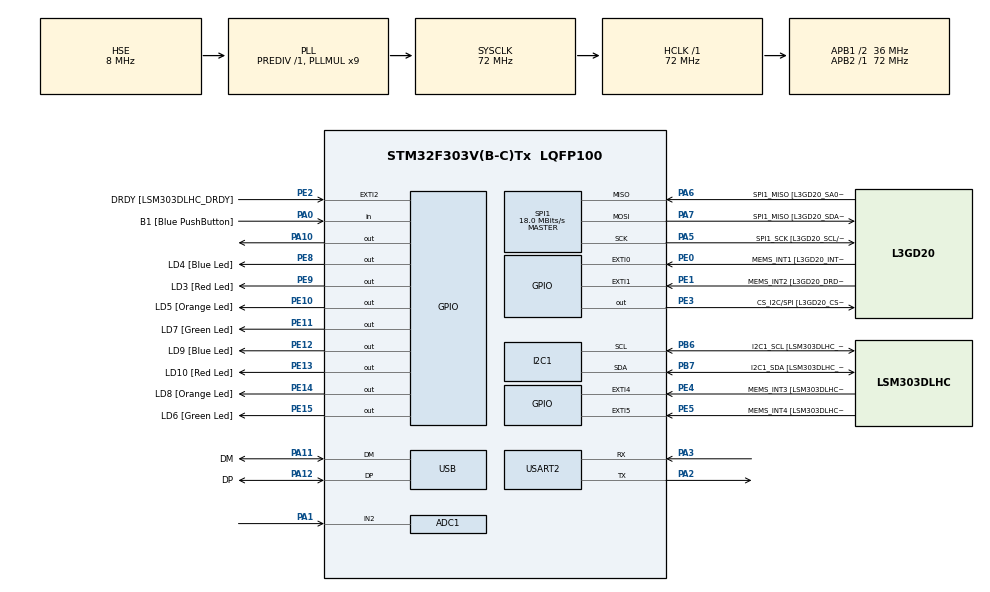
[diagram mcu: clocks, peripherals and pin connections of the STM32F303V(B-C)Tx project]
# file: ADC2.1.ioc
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ADC1.Channel-0\#ChannelRegularConversion=ADC_CHANNEL_2
ADC1.ContinuousConvMode=DISABLE
ADC1.NbrOfConversionFlag=1
ADC1.Offset-0\#ChannelRegularConversion=0
ADC1.OffsetNumber-0\#ChannelRegularConversion=ADC_OFFSET_NONE
ADC1.Rank-0\#ChannelRegularConversion=1
ADC1.SamplingTime-0\#ChannelRegularConversion=ADC_SAMPLETIME_19CYCLES_5
ADC1.SamplingTimeOPAMP-0\#ChannelRegularConversion=ADC_SAMPLETIME_19CYCLES_5
ADC1.master=1
Dma.ADC1.0.Direction=DMA_PERIPH_TO_MEMORY
Dma.ADC1.0.Instance=DMA1_Channel1
Dma.ADC1.0.MemDataAlignment=DMA_MDATAALIGN_WORD
Dma.ADC1.0.MemInc=DMA_MINC_ENABLE
Dma.ADC1.0.Mode=DMA_CIRCULAR
Dma.ADC1.0.PeriphDataAlignment=DMA_PDATAALIGN_WORD
Dma.ADC1.0.PeriphInc=DMA_PINC_DISABLE
Dma.ADC1.0.Priority=DMA_PRIORITY_LOW
Dma.Request0=ADC1
I2C1.Timing-I2C=0x2000090E
Mcu.Family=STM32F3
Mcu.Name=STM32F303V(B-C)Tx
Mcu.Package=LQFP100
NVIC.DMA1_Channel1_IRQn=true\:0\:0\:false\:false\:true\:false\:true\:true
NVIC.PriorityGroup=NVIC_PRIORITYGROUP_0
PA0.GPIO_Label=B1 [Blue PushButton]
PA0.Signal=GPIO_Input
PA1.Mode=IN2-Single-Ended
PA1.Signal=ADC1_IN2
PA10.Signal=GPIO_Output
PA11.GPIO_Label=DM
PA11.Mode=Device
PA11.Signal=USB_DM
PA12.GPIO_Label=DP
PA12.Mode=Device
PA12.Signal=USB_DP
PA13.GPIO_Label=SWDIO
PA13.Mode=Serial_Wire
PA13.Signal=SYS_JTMS-SWDIO
PA14.GPIO_Label=SWCLK
PA14.Mode=Serial_Wire
PA14.Signal=SYS_JTCK-SWCLK
PA2.Mode=Asynchronous
PA2.Signal=USART2_TX
PA3.Mode=Asynchronous
PA3.Signal=USART2_RX
PA5.GPIO_Label=SPI1_SCK [L3GD20_SCL/SPC]
PA5.Mode=Full_Duplex_Master
PA5.Signal=SPI1_SCK
PA6.GPIO_Label=SPI1_MISO [L3GD20_SA0/SDO]
PA6.Mode=Full_Duplex_Master
PA6.Signal=SPI1_MISO
PA7.GPIO_Label=SPI1_MISO [L3GD20_SDA/SDI/SDO]
PA7.Mode=Full_Duplex_Master
PA7.Signal=SPI1_MOSI
PB3.GPIO_Label=SWO
PB3.Signal=SYS_JTDO-TRACESWO
PB6.GPIO_Label=I2C1_SCL [LSM303DLHC_SCL]
PB6.GPIO_Pu=GPIO_PULLUP
PB6.Mode=I2C
PB6.Signal=I2C1_SCL
PB7.GPIO_Label=I2C1_SDA [LSM303DLHC_SDA]
PB7.GPIO_Pu=GPIO_PULLUP
PB7.Mode=I2C
PB7.Signal=I2C1_SDA
PC14-OSC32_IN.GPIO_Label=OSC32_IN
PC14-OSC32_IN.Signal=RCC_OSC32_IN
PC15-OSC32_OUT.GPIO_Label=OSC32_OUT
PC15-OSC32_OUT.Signal=RCC_OSC32_OUT
PE0.GPIO_Label=MEMS_INT1 [L3GD20_INT1]
PE0.GPIO_ModeDefaultEXTI=GPIO_MODE_EVT_RISING
PE0.Signal=GPXTI0
PE1.GPIO_Label=MEMS_INT2 [L3GD20_DRDY/INT2]
PE1.GPIO_ModeDefaultEXTI=GPIO_MODE_EVT_RISING
PE1.Signal=GPXTI1
PE10.GPIO_Label=LD5 [Orange Led]
PE10.Signal=GPIO_Output
PE11.GPIO_Label=LD7 [Green Led]
PE11.Signal=GPIO_Output
PE12.GPIO_Label=LD9 [Blue Led]
PE12.Signal=GPIO_Output
PE13.GPIO_Label=LD10 [Red Led]
PE13.Signal=GPIO_Output
PE14.GPIO_Label=LD8 [Orange Led]
PE14.Signal=GPIO_Output
PE15.GPIO_Label=LD6 [Green Led]
PE15.Signal=GPIO_Output
PE2.GPIO_Label=DRDY [LSM303DLHC_DRDY]
PE2.GPIO_ModeDefaultEXTI=GPIO_MODE_EVT_RISING
PE2.Signal=GPXTI2
PE3.GPIO_Label=CS_I2C/SPI [L3GD20_CS_I2C/SPI]
PE3.Signal=GPIO_Output
PE4.GPIO_Label=MEMS_INT3 [LSM303DLHC_INT1]
PE4.GPIO_ModeDefaultEXTI=GPIO_MODE_EVT_RISING
PE4.Signal=GPXTI4
PE5.GPIO_Label=MEMS_INT4 [LSM303DLHC_INT2]
PE5.GPIO_ModeDefaultEXTI=GPIO_MODE_EVT_RISING
PE5.Signal=GPXTI5
PE8.GPIO_Label=LD4 [Blue Led]
PE8.Signal=GPIO_Output
PE9.GPIO_Label=LD3 [Red Led]
PE9.Signal=GPIO_Output
PF0-OSC_IN.GPIO_Label=OSC_IN
PF0-OSC_IN.Mode=HSE-External-Oscillator
PF0-OSC_IN.Signal=RCC_OSC_IN
PF1-OSC_OUT.GPIO_Label=OSC_OUT
PF1-OSC_OUT.Mode=HSE-External-Oscillator
PF1-OSC_OUT.Signal=RCC_OSC_OUT
ProjectManager.HeapSize=0x200
ProjectManager.StackSize=0x400
ProjectManager.TargetToolchain=MDK-ARM V5.32
RCC.AHBFreq_Value=72000000
RCC.APB1CLKDivider=RCC_HCLK_DIV2
RCC.APB1Freq_Value=36000000
RCC.APB1TimFreq_Value=72000000
RCC.APB2Freq_Value=72000000
RCC.APB2TimFreq_Value=72000000
RCC.CortexFreq_Value=72000000
RCC.HCLKFreq_Value=72000000
RCC.HSE_VALUE=8000000
RCC.HSI_VALUE=8000000
RCC.LSE_VALUE=32768
RCC.PLLMUL=RCC_PLL_MUL9
RCC.PRESCALERUSB=RCC_USBCLKSOURCE_PLL_DIV1_5
RCC.SYSCLKFreq_VALUE=72000000
RCC.SYSCLKSourceVirtual=RCC_SYSCLKSOURCE_PLLCLK
RCC.USBFreq_Value=48000000
SPI1.BaudRatePrescaler=SPI_BAUDRATEPRESCALER_4
SPI1.BaudRatePrescaler-Full_Duplex_Master=SPI_BAUDRATEPRESCALER_2
SPI1.CalculateBaudRate=18.0 MBits/s
SPI1.CalculateBaudRate-Full_Duplex_Master=24.0 MBits/s
SPI1.Direction=SPI_DIRECTION_2LINES
SPI1.Mode=SPI_MODE_MASTER
SPI1.Mode-Full_Duplex_Master=SPI_MODE_MASTER
SPI1.VirtualType=VM_MASTER
USART2.VirtualMode-Asynchronous=VM_ASYNC
board=STM32F3DISCOVERY

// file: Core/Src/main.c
/* USER CODE BEGIN Header */
/**
  ******************************************************************************
  * @file           : main.c
  * @brief          : Main program body
  ******************************************************************************
  * @attention
  *
  * Copyright (c) 2022 STMicroelectronics.
  * All rights reserved.
  *
  * This software is licensed under terms that can be found in the LICENSE file
  * in the root directory of this software component.
  * If no LICENSE file comes with this software, it is provided AS-IS.
  *
  ******************************************************************************
  */
/* USER CODE END Header */
#include "main.h"
#include "adc.h"
#include "dma.h"
#include "i2c.h"
#include "spi.h"
#include "usart.h"
#include "gpio.h"

/* USER CODE BEGIN Includes */
   #include <string.h>
	 #include <stdio.h>
/* USER CODE END Includes */

void SystemClock_Config(void);

int main(void)
{
  /* USER CODE BEGIN 1 */
     uint16_t raw;
	   char msg[10];
  /* USER CODE END 1 */

  /* MCU Configuration--------------------------------------------------------*/

  /* Reset of all peripherals, Initializes the Flash interface and the Systick. */
  HAL_Init();

  /* Configure the system clock */
  SystemClock_Config();

  /* Initialize all configured peripherals */
  MX_GPIO_Init();
  MX_DMA_Init();
  MX_ADC1_Init();
  MX_I2C1_Init();
  MX_SPI1_Init();
  //MX_USB_PCD_Init();
  MX_USART2_UART_Init();
  /* USER CODE BEGIN 2 */
	//GET ADC VALUE
		HAL_ADC_Start(&hadc1);
		HAL_ADC_PollForConversion(&hadc1, HAL_MAX_DELAY);
  /* USER CODE END 2 */

  /* Infinite loop */
  /* USER CODE BEGIN WHILE */
  while (1)
  {
		//test:set gpio pin high
		//HAL_GPIO_WritePin(GPIOA, GPIO_PIN_10, GPIO_PIN_SET);

		raw= HAL_ADC_GetValue(&hadc1);

		//TEST: SET GPIO PIN LOW
		HAL_GPIO_WritePin(GPIOA, GPIO_PIN_10, GPIO_PIN_RESET);

		//Convert to string and print
		sprintf(msg, "%hu\r\n", raw);
		HAL_UART_Transmit(&huart2, (uint8_t*)msg, strlen(msg), HAL_MAX_DELAY);

		HAL_Delay(1);

    /* USER CODE END WHILE */

  }
}

void SystemClock_Config(void)
{
  RCC_OscInitTypeDef RCC_OscInitStruct = {0};
  RCC_ClkInitTypeDef RCC_ClkInitStruct = {0};
  RCC_PeriphCLKInitTypeDef PeriphClkInit = {0};

  /** Initializes the RCC Oscillators according to the specified parameters
  * in the RCC_OscInitTypeDef structure.
  */
  RCC_OscInitStruct.OscillatorType = RCC_OSCILLATORTYPE_HSI|RCC_OSCILLATORTYPE_HSE;
  RCC_OscInitStruct.HSEState = RCC_HSE_ON;
  RCC_OscInitStruct.HSEPredivValue = RCC_HSE_PREDIV_DIV1;
  RCC_OscInitStruct.HSIState = RCC_HSI_ON;
  RCC_OscInitStruct.HSICalibrationValue = RCC_HSICALIBRATION_DEFAULT;
  RCC_OscInitStruct.PLL.PLLState = RCC_PLL_ON;
  RCC_OscInitStruct.PLL.PLLSource = RCC_PLLSOURCE_HSE;
  RCC_OscInitStruct.PLL.PLLMUL = RCC_PLL_MUL9;
  if (HAL_RCC_OscConfig(&RCC_OscInitStruct) != HAL_OK)
  {
    Error_Handler();
  }

  /** Initializes the CPU, AHB and APB buses clocks
  */
  RCC_ClkInitStruct.ClockType = RCC_CLOCKTYPE_HCLK|RCC_CLOCKTYPE_SYSCLK
                              |RCC_CLOCKTYPE_PCLK1|RCC_CLOCKTYPE_PCLK2;
  RCC_ClkInitStruct.SYSCLKSource = RCC_SYSCLKSOURCE_PLLCLK;
  RCC_ClkInitStruct.AHBCLKDivider = RCC_SYSCLK_DIV1;
  RCC_ClkInitStruct.APB1CLKDivider = RCC_HCLK_DIV2;
  RCC_ClkInitStruct.APB2CLKDivider = RCC_HCLK_DIV1;

  if (HAL_RCC_ClockConfig(&RCC_ClkInitStruct, FLASH_LATENCY_2) != HAL_OK)
  {
    Error_Handler();
  }
  PeriphClkInit.PeriphClockSelection = RCC_PERIPHCLK_USB|RCC_PERIPHCLK_USART2
                              |RCC_PERIPHCLK_I2C1|RCC_PERIPHCLK_ADC12;
  PeriphClkInit.Usart2ClockSelection = RCC_USART2CLKSOURCE_PCLK1;
  PeriphClkInit.Adc12ClockSelection = RCC_ADC12PLLCLK_DIV1;
  PeriphClkInit.I2c1ClockSelection = RCC_I2C1CLKSOURCE_HSI;
  PeriphClkInit.USBClockSelection = RCC_USBCLKSOURCE_PLL_DIV1_5;
  if (HAL_RCCEx_PeriphCLKConfig(&PeriphClkInit) != HAL_OK)
  {
    Error_Handler();
  }
}

void Error_Handler(void)
{
  __disable_irq();
  while (1)
  {
  }
}
